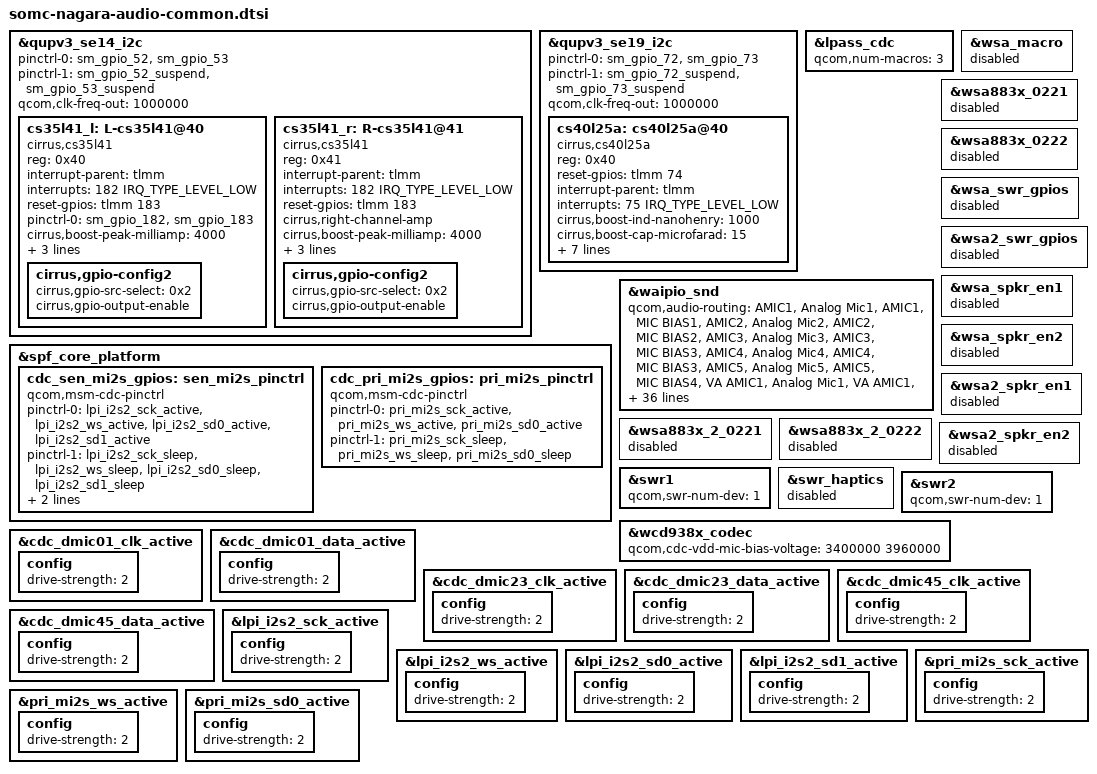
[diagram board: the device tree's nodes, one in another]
&qupv3_se14_i2c {
	pinctrl-0 = <&sm_gpio_52 &sm_gpio_53>;
	pinctrl-1 = <&sm_gpio_52_suspend &sm_gpio_53_suspend>;
	qcom,clk-freq-out = <1000000>;
	status = "okay";

	cs35l41_l: L-cs35l41@40 {
		compatible = "cirrus,cs35l41";
		reg = <0x40>;
		interrupt-parent = <&tlmm>;
		interrupts = <182 IRQ_TYPE_LEVEL_LOW>;
		reset-gpios = <&tlmm 183 0>;		/*GPIO_ACTIVE_HIGH = 0*/
		pinctrl-names = "default";
		pinctrl-0 = <&sm_gpio_182>, <&sm_gpio_183>;
		cirrus,boost-peak-milliamp = <4000>;
		cirrus,boost-ind-nanohenry = <1000>;
		cirrus,boost-cap-microfarad = <15>;
		cirrus,asp-sdout-hiz = <3>;
		cirrus,gpio-config2 {
			cirrus,gpio-src-select = <0x2>;
			cirrus,gpio-output-enable;
		};
	};

	cs35l41_r: R-cs35l41@41 {
		compatible = "cirrus,cs35l41";
		reg = <0x41>;
		interrupt-parent = <&tlmm>;
		interrupts = <182 IRQ_TYPE_LEVEL_LOW>;
		reset-gpios = <&tlmm 183 0>;		/*GPIO_ACTIVE_HIGH = 0*/
		cirrus,right-channel-amp;
		cirrus,boost-peak-milliamp = <4000>;
		cirrus,boost-ind-nanohenry = <1000>;
		cirrus,boost-cap-microfarad = <15>;
		cirrus,asp-sdout-hiz = <3>;
		cirrus,gpio-config2 {
			cirrus,gpio-src-select = <0x2>;
			cirrus,gpio-output-enable;
		};
	};
};

&qupv3_se19_i2c {
	pinctrl-0 = <&sm_gpio_72 &sm_gpio_73>;
	pinctrl-1 = <&sm_gpio_72_suspend &sm_gpio_73_suspend>;
	qcom,clk-freq-out = <1000000>;
	status = "okay";

	cs40l25a: cs40l25a@40 {
		compatible = "cirrus,cs40l25a";
		reg = <0x40>;
		reset-gpios = <&tlmm 74 0>;		/*GPIO_ACTIVE_HIGH = 0*/
		interrupt-parent = <&tlmm>;
		interrupts = <75 IRQ_TYPE_LEVEL_LOW>;
		cirrus,boost-ind-nanohenry = <1000>;
		cirrus,boost-cap-microfarad = <15>;
		cirrus,boost-ipk-milliamp = <3500>;
		cirrus,hiber-enable;
		cirrus,fw-id-remap = <0x1400D0>;
		cirrus,f0-default = <2801664>;
		cirrus,f0-min = <2637824>;
		cirrus,f0-max = <2965504>;
		/* cirrus,redc-default = <223787>; */
		/* cirrus,redc-min = <111893>; */
		/* cirrus,redc-max = <447574>; */
		cirrus,auto-recovery;
	};
};

&spf_core_platform {
	cdc_sen_mi2s_gpios: sen_mi2s_pinctrl {
		status = "ok";
		compatible = "qcom,msm-cdc-pinctrl";
		pinctrl-names = "aud_active", "aud_sleep";
		pinctrl-0 = <&lpi_i2s2_sck_active &lpi_i2s2_ws_active
			     &lpi_i2s2_sd0_active &lpi_i2s2_sd1_active>;
		pinctrl-1 = <&lpi_i2s2_sck_sleep &lpi_i2s2_ws_sleep
			     &lpi_i2s2_sd0_sleep &lpi_i2s2_sd1_sleep>;
		qcom,lpi-gpios;
		qcom,tlmm-pins = <176 181>;
	};

	cdc_pri_mi2s_gpios: pri_mi2s_pinctrl {
		compatible = "qcom,msm-cdc-pinctrl";
		pinctrl-names = "aud_active", "aud_sleep";
		pinctrl-0 = <&pri_mi2s_sck_active &pri_mi2s_ws_active
			 &pri_mi2s_sd0_active>;
		pinctrl-1 = <&pri_mi2s_sck_sleep &pri_mi2s_ws_sleep
			 &pri_mi2s_sd0_sleep>;
	};
};

&lpass_cdc {
	qcom,num-macros = <3>;
};

&waipio_snd {
	qcom,audio-routing =
		"AMIC1", "Analog Mic1",
		"AMIC1", "MIC BIAS1",
		"AMIC2", "Analog Mic2",
		"AMIC2", "MIC BIAS2",
		"AMIC3", "Analog Mic3",
		"AMIC3", "MIC BIAS3",
		"AMIC4", "Analog Mic4",
		"AMIC4", "MIC BIAS3",
		"AMIC5", "Analog Mic5",
		"AMIC5", "MIC BIAS4",
		"VA AMIC1", "Analog Mic1",
		"VA AMIC1", "VA MIC BIAS1",
		"VA AMIC2", "Analog Mic2",
		"VA AMIC2", "VA MIC BIAS2",
		"VA AMIC3", "Analog Mic3",
		"VA AMIC3", "VA MIC BIAS3",
		"VA AMIC4", "Analog Mic4",
		"VA AMIC4", "VA MIC BIAS3",
		"VA AMIC5", "Analog Mic5",
		"VA AMIC5", "VA MIC BIAS4",
		"TX DMIC0", "Digital Mic0",
		"Digital Mic0", "MIC BIAS3",
		"TX DMIC1", "Digital Mic1",
		"Digital Mic1", "MIC BIAS3",
		"TX DMIC2", "Digital Mic2",
		"Digital Mic2", "MIC BIAS1",
		"TX DMIC3", "Digital Mic3",
		"Digital Mic3", "MIC BIAS1",
		"IN1_HPHL", "HPHL_OUT",
		"IN2_HPHR", "HPHR_OUT",
		"IN3_AUX", "AUX_OUT",
		"RX_TX DEC0_INP", "TX DEC0 MUX",
		"RX_TX DEC1_INP", "TX DEC1 MUX",
		"RX_TX DEC2_INP", "TX DEC2 MUX",
		"RX_TX DEC3_INP", "TX DEC3 MUX",
		"TX SWR_INPUT", "WCD_TX_OUTPUT",
		"VA SWR_INPUT", "VA_SWR_CLK",
		"VA SWR_INPUT", "WCD_TX_OUTPUT",
		"VA_AIF1 CAP", "VA_SWR_CLK",
		"VA_AIF2 CAP", "VA_SWR_CLK",
		"VA_AIF3 CAP", "VA_SWR_CLK",
		"VA DMIC0", "Digital Mic0",
		"VA DMIC1", "Digital Mic1",
		"VA DMIC2", "Digital Mic2",
		"VA DMIC3", "Digital Mic3",
		"Digital Mic0", "VA MIC BIAS3",
		"Digital Mic1", "VA MIC BIAS3",
		"Digital Mic2", "VA MIC BIAS1",
		"Digital Mic3", "VA MIC BIAS1";
	qcom,msm-mbhc-usbc-audio-supported = <0>;
	qcom,msm-mbhc-hphl-swh = <1>;
	qcom,msm-mbhc-gnd-swh = <1>;

	asoc-codec  = <&stub_codec>, <&lpass_cdc>,
		      <&cs35l41_l>, <&cs35l41_r>,
		      <&cs40l25a>,
		      <&wcd938x_codec>;
	asoc-codec-names = "msm-stub-codec.1", "lpass-cdc",
			   "cs35l41_l", "cs35l41_r",
			   "cs40l2x-codec",
			   "wcd938x_codec";
	qcom,wsa-max-devs = <0>;
	qcom,sen-mi2s-gpios = <&cdc_sen_mi2s_gpios>;
	qcom,pri-mi2s-gpios = <&cdc_pri_mi2s_gpios>;
};

&wsa_macro{
	status = "disabled";
};

&wsa883x_0221{
	status = "disabled";
};

&wsa883x_0222{
	status = "disabled";
};

&wsa883x_2_0221{
	status = "disabled";
};

&wsa883x_2_0222{
	status = "disabled";
};

&wsa_swr_gpios{
	status = "disabled";
};

&wsa2_swr_gpios{
	status = "disabled";
};

&wsa_spkr_en1{
	status = "disabled";
};

&wsa_spkr_en2{
	status = "disabled";
};

&wsa2_spkr_en1{
	status = "disabled";
};

&wsa2_spkr_en2{
	status = "disabled";
};

&swr1{
	qcom,swr-num-dev = <1>;
};

&swr_haptics{
	status = "disabled";
};

&swr2{
	qcom,swr-num-dev = <1>;
};

&wcd938x_codec{
	qcom,cdc-vdd-mic-bias-voltage = <3400000 3960000>;
};

&cdc_dmic01_clk_active {
	config {
		drive-strength = <2>;
	};
};

&cdc_dmic01_data_active {
	config {
		drive-strength = <2>;
	};
};

&cdc_dmic23_clk_active {
	config {
		drive-strength = <2>;
	};
};

&cdc_dmic23_data_active {
	config {
		drive-strength = <2>;
	};
};

&cdc_dmic45_clk_active {
	config {
		drive-strength = <2>;
	};
};

&cdc_dmic45_data_active {
	config {
		drive-strength = <2>;
	};
};

&lpi_i2s2_sck_active {
	config {
		drive-strength = <2>;
	};
};

&lpi_i2s2_ws_active {
	config {
		drive-strength = <2>;
	};
};

&lpi_i2s2_sd0_active {
	config {
		drive-strength = <2>;
	};
};

&lpi_i2s2_sd1_active {
	config {
		drive-strength = <2>;
	};
};

&pri_mi2s_sck_active  {
	config {
		drive-strength = <2>;
	};
};

&pri_mi2s_ws_active {
	config {
		drive-strength = <2>;
	};
};

&pri_mi2s_sd0_active {
	config {
		drive-strength = <2>;
	};
};

